# IND83212 register map
Series: Verne; File version: B0
CPU: CM0 r0p1, selectable endian, no MPU, no FPU, 4 interrupt priority bits
Registers are 32-bit, read-write, no defined reset value unless marked. A register's access mark holds for its fields unless they carry their own. Offsets are from the block's base; [hi:lo] are bit positions; <NAME> marks a mode.

## GPIO — GPIO bit control and configuration
Base 0x50018000; register names take the prefix GPIO_
0x00 GPADATA — GPIO Port A Data
  [4:0] GPADATA<1024> dual — Port A data. To aid in the efficiency of software, the GPIO ports allow for the modification of individual bits in the GPIO Data by using bits [7:0] of the address bus as a enable. In this manner, software drivers can modify individual GPIO pins in a single instruction without affecting the state of the other pins. This method is more efficient than the conventional method of performing a read-modify-write operation to set or clear an individual GPIO pin. To write all the bits at the same time use address offset of 0x03.
0x800 GPENA — GPIO Port Enables
  [0] GPAENA — Enables the Clock-Gate, can be cleared to save power, if none of the GPIO functionality is required
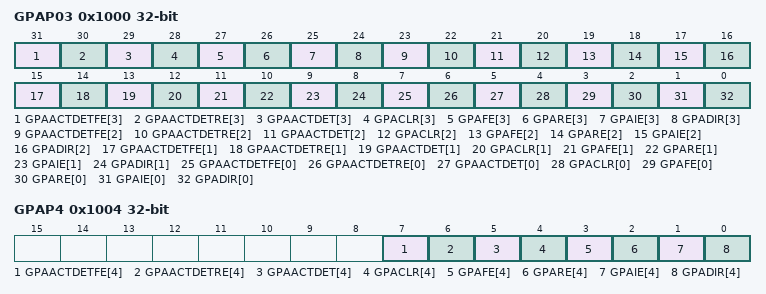
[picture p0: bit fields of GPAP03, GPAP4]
0x1000 GPAP03 — GPIO Port A Pin 0-3 Control
  [31] GPAACTDETFE[3] ro — GPIO3 PIN activity fall status.
  [30] GPAACTDETRE[3] ro — GPIO3 PIN activity rise status.
  [29] GPAACTDET[3] ro — GPIO3 PIN activity interrupt.
  [28] GPACLR[3] wo — GPIO3 PIN interrupt clear. Autoclear: includes a synchronous reset signal which clears the register on the cycle following write.
  [27] GPAFE[3] — GPIO3 PIN falling edge enable.
  [26] GPARE[3] — GPIO3 PIN rising edge enable.
  [25] GPAIE[3] — GPIO3 PIN interrupt mask.
  [24] GPADIR[3] — GPIO3 PIN output enable.
  [23] GPAACTDETFE[2] ro — LIN_IN PIN activity fall status.
  [22] GPAACTDETRE[2] ro — LIN_IN PIN activity rise status.
  [21] GPAACTDET[2] ro — LIN_IN PIN activity interrupt.
  [20] GPACLR[2] wo — LIN_IN PIN interrupt clear. Autoclear: includes a synchronous reset signal which clears the register on the cycle following write.
  [19] GPAFE[2] — LIN_IN PIN falling edge enable.
  [18] GPARE[2] — LIN_IN PIN rising edge enable.
  [17] GPAIE[2] — LIN_IN PIN interrupt mask.
  [16] GPADIR[2] — NOT USED. SEE IOCTRL RxLIN_ena & TxLIN_ena.
  [15] GPAACTDETFE[1] ro — GPIO2 PIN activity fall status.
  [14] GPAACTDETRE[1] ro — GPIO2 PIN activity rise status.
  [13] GPAACTDET[1] ro — GPIO2 PIN activity interrupt.
  [12] GPACLR[1] wo — GPIO2 PIN interrupt clear. Autoclear: includes a synchronous reset signal which clears the register on the cycle following write.
  [11] GPAFE[1] — GPIO2 PIN falling edge enable.
  [10] GPARE[1] — GPIO2 PIN rising edge enable.
  [9] GPAIE[1] — GPIO2 PIN interrupt mask.
  [8] GPADIR[1] — GPIO2 PIN output enable.
  [7] GPAACTDETFE[0] ro — GPIO1 PIN activity fall status.
  [6] GPAACTDETRE[0] ro — GPIO1 PIN activity rise status.
  [5] GPAACTDET[0] ro — GPIO1 PIN activity interrupt.
  [4] GPACLR[0] wo — GPIO1 PIN interrupt clear. Autoclear: includes a synchronous reset signal which clears the register on the cycle following write.
  [3] GPAFE[0] — GPIO1 PIN falling edge enable.
  [2] GPARE[0] — GPIO1 PIN rising edge enable.
  [1] GPAIE[0] — GPIO1 PIN interrupt mask.
  [0] GPADIR[0] — GPIO1 PIN output enable.
0x1004 GPAP4 — GPIO Port A Pin 4 Control
  [7] GPAACTDETFE[4] ro — GPIO4 PIN activity fall status.
  [6] GPAACTDETRE[4] ro — GPIO4 PIN activity rise status.
  [5] GPAACTDET[4] ro — GPIO4 PIN activity interrupt.
  [4] GPACLR[4] wo — GPIO4 PIN interrupt clear. Autoclear: includes a synchronous reset signal which clears the register on the cycle following write.
  [3] GPAFE[4] — GPIO4 PIN falling edge enable.
  [2] GPARE[4] — GPIO4 PIN rising edge enable.
  [1] GPAIE[4] — GPIO4 PIN interrupt mask.
  [0] GPADIR[4] — GPIO4 PIN output enable.

## TIMER0 — General purpose timer 0 registers
Base 0x50020000; register names take the prefix TIMER0_
0x00 COUNT — Timer Counter Register
  [31:0] COUNT — Count. Initial counter value. The timer will count from this value to 0xFFFFFFFF and roll over to 0x00000000. At this point it will generate an interrupt if enabled. The interrupt routine is responsible for reloading the value if needed as this timer does not auto-reload the original content.
0x04 CFG — Timer Control Register
  [0] ENA — Enable. This bit starts/stops the timer: < br> 1 = Timer Running < br> 0 = Timer Inactive

## TIMER1 — General purpose timer 1 registers
Base 0x50020008; register names take the prefix TIMER1_
Registers as TIMER0.

## TIMER2 — General purpose timer 2 registers
Base 0x50020010; register names take the prefix TIMER2_
Registers as TIMER0.

## WDT1 — The watchdog timer that is local to VERNE MCU
Base 0x50020018; register names take the prefix WDT1_
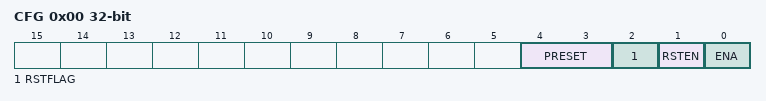
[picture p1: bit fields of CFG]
0x00 CFG — Config
  [4:3] PRESET — Preset. Defines the watchdog timeout period. It means that the WDT internal counter will count from 0 to the prescaler value at the system clock speed and trigger if not cleared. For instance, a system running from a 30MHz Crystal with WDTPRES[1I0] = 10 will trigger the WDT after approximately 0.14 seconds if not cleared properly and in time by the application. 0x0: 2^13 / System Clock 0x1: 2^19 / System Clock 0x2: 2^22 / System Clock 0x3: 2^32 / System Clock
  [2] RSTFLAG — Reset flag. This flag is set by the system at the initialization if the initialization was caused by a reset triggered by the WDT. The bit can be cleared by the application.
  [1] RSTEN — Reset enable. If enabled a WDT time-out will force the microcontroller to reset. This bit can be asserted but it cannot be de-asserted.
  [0] ENA — WDT Enable. This bit can be asserted but it cannot be de-asserted. It means that once the WDT is enabled it cannot be turned off until a Reset or Power-On Reset occurs.
0x04 KEY
  [31:0] KEY — Key. To clear the WDT counting the following words must be written in this order and without any other instruction between then: 0x3C570001 0x007F4AD6
